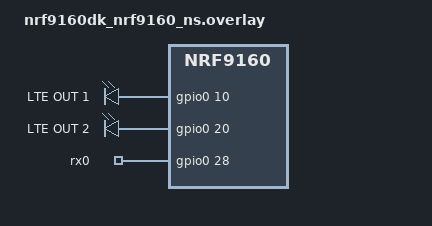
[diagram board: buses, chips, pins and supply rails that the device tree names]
/*
 * Copyright (c) 2022 Achim Kraus CloudCoap.net
 *
 * See the NOTICE file(s) distributed with this work for additional
 * information regarding copyright ownership.
 *
 * This program and the accompanying materials are made available under the
 * terms of the Eclipse Public License 2.0 which is available at
 * http://www.eclipse.org/legal/epl-2.0
 *
 * SPDX-License-Identifier: EPL-2.0
 */

/*
 * Add outputs for LTE states "RRC connected" "LTE ready"
 * (ready := connected, PDN active, registered). 
 */ 

/	{

	outs {
		compatible = "gpio-leds";
		status = "okay";
		
		out1: out_1 {
			gpios = <&gpio0 10 0>;
			label = "LTE OUT 1";
		};

		out2: out_2 {
			gpios = <&gpio0 20 0>;
			label = "LTE OUT 2";
		};
	};

	ins {
		compatible = "gpio-keys";
		rx0: uart0_rx {
			gpios = <&gpio0 28 0>;
		};
	};

	aliases {
		out1 = &out1;
		out2 = &out2;

//		appl-storage-flash = &mx25r64;
	};

};

&uart0_default {
	group2 {
/* 		psels = <NRF_PSEL(UART_RX, 0, 28)>,
		<NRF_PSEL(UART_CTS, 0, 26)>; */
		/delete-property/ bias-pull-up;
	};
};

&spi3 {
	cs-gpios = <&arduino_header 16 GPIO_ACTIVE_LOW>, /* D10 */
		   <&gpio0 25 GPIO_ACTIVE_LOW>;
	mx25r64: mx25r6435f@1 {
		compatible = "jedec,spi-nor";
		status = "disabled";
		reg = <1>;
		spi-max-frequency = <8000000>;
		jedec-id = [c2 28 17];
		sfdp-bfp = [
			e5 20 f1 ff  ff ff ff 03  44 eb 08 6b  08 3b 04 bb
			ee ff ff ff  ff ff 00 ff  ff ff 00 ff  0c 20 0f 52
			10 d8 00 ff  23 72 f5 00  82 ed 04 cc  44 83 48 44
			30 b0 30 b0  f7 c4 d5 5c  00 be 29 ff  f0 d0 ff ff
		];
		size = <67108864>;
		mxicy,mx25r-power-mode = "low-power";
		has-dpd;
		t-enter-dpd = <10000>;
		t-exit-dpd = <35000>;
	};
};

sensor_i2c: &i2c2 {};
